# APM32L08x register map
File version: 1.0
CPU: CM0+ r0p0, little endian, MPU, no FPU, 4 interrupt priority bits
Registers are 32-bit, read-write, reset 0x0 unless marked. A register's access mark holds for its fields unless they carry their own. Offsets are from the block's base; [hi:lo] are bit positions.

## CRS — Clock recovery system
Base 0x40006C00
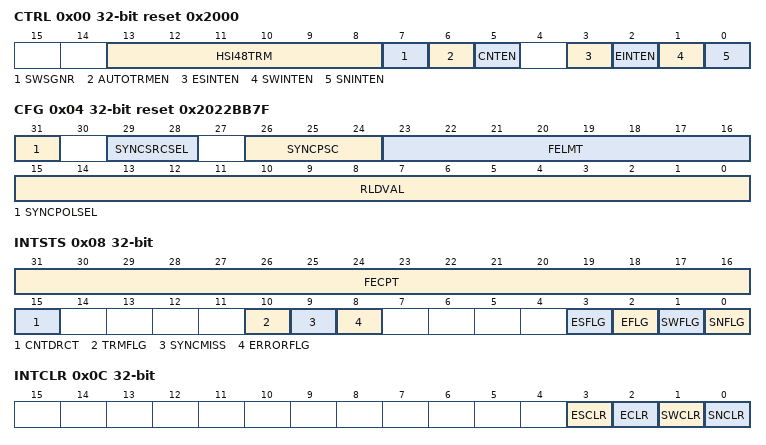
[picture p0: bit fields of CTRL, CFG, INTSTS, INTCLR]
0x00 CTRL reset 0x2000 — control register
  [13:8] HSI48TRM — HSI48 oscillator smooth trimming
  [7] SWSGNR — Generate software SYNC event
  [6] AUTOTRMEN — Automatic trimming enable
  [5] CNTEN — Frequency error counter enable
  [3] ESINTEN — Expected SYNC interrupt enable
  [2] EINTEN — Synchronization or trimming error interrupt enable
  [1] SWINTEN — SYNC warning interrupt enable
  [0] SNINTEN — SYNC event OK interrupt enable
0x04 CFG reset 0x2022BB7F — configuration register
  [31] SYNCPOLSEL — SYNC polarity selection
  [29:28] SYNCSRCSEL — SYNC signal source selection
  [26:24] SYNCPSC — SYNC divider
  [23:16] FELMT — Frequency error limit
  [15:0] RLDVAL — Counter reload value
0x08 INTSTS ro — interrupt and status register
  [31:16] FECPT — Frequency error capture
  [15] CNTDRCT — Frequency error direction
  [10] TRMFLG — Trimming overflow or underflow
  [9] SYNCMISS — SYNC missed
  [8] ERRORFLG — SYNC error
  [3] ESFLG — Expected SYNC flag
  [2] EFLG — Error flag
  [1] SWFLG — SYNC warning flag
  [0] SNFLG — SYNC event OK flag
0x0C INTCLR — interrupt flag clear register
  [3] ESCLR — Expected SYNC clear flag
  [2] ECLR — Error clear flag
  [1] SWCLR — SYNC warning clear flag
  [0] SNCLR — SYNC event OK clear flag

## CRC — Cyclic redundancy check calculation unit
Base 0x40023000
0x00 DATA reset 0xFFFFFFFF
  [31:0] DATA — 32bit Data
0x04 INDATA — Independent data register
  [7:0] INDATA — Independent 8bit Data
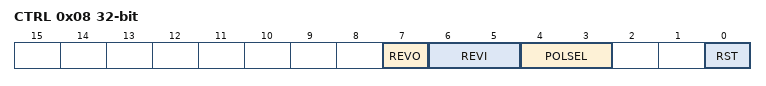
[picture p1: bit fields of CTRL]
0x08 CTRL access per field — Control register
  [7] REVO rw — Reverse output data
  [6:5] REVI rw — Reverse input data
  [4:3] POLSEL rw — Polynomial size
  [0] RST wo — Reset CRC Calculation Unit
0x10 INITVAL reset 0xFFFFFFFF — Initial CRC value
  [31:0] VALUE — Programmable initial CRC value
0x14 POL reset 0x4C11DB7 — polynomial
  [31:0] PPOL — Programmable polynomial

## DAC — Digital-to-analog converter
Base 0x40007400
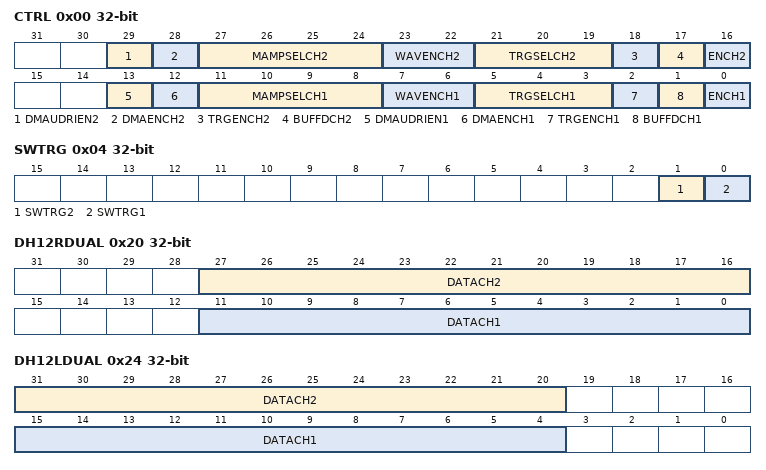
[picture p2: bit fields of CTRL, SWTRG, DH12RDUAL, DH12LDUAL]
0x00 CTRL — control register
  [29] DMAUDRIEN2 — DAC Channel2 DMA Underrun Interrupt Enable
  [28] DMAENCH2 — DAC channel2DMA enable
  [27:24] MAMPSELCH2 — Select DAC Channel2 LFSR Bit Mask/Triangle Wave Amplitude Selector
  [23:22] WAVENCH2 — DAC Channel2 Noise/Triangle Wave Generation Enable
  [21:19] TRGSELCH2 — DAC Channel2 Trigger Source Select
  [18] TRGENCH2 — DAC Channel2 Trigger Enable
  [17] BUFFDCH2 — DAC Channel2 Output Buffer Disable
  [16] ENCH2 — DAC Channel2 Enable
  [13] DMAUDRIEN1 — DAC channel1 DMA Underrun Interrupt enable
  [12] DMAENCH1 — DAC channel1 DMA enable
  [11:8] MAMPSELCH1 — DAC channel1 mask/amplitude selector
  [7:6] WAVENCH1 — DAC channel1 noise/triangle wave generation enable
  [5:3] TRGSELCH1 — DAC channel1 trigger selection
  [2] TRGENCH1 — DAC channel1 trigger enable
  [1] BUFFDCH1 — DAC channel1 output buffer disable
  [0] ENCH1 — DAC channel1 enable
0x04 SWTRG wo — software trigger register
  [1] SWTRG2 — DAC Channel2 Software Trigger Enable
  [0] SWTRG1 — DAC Channel1 Software Trigger Enable
0x08 DH12R1 — channel1 12-bit right-aligned data holding register
  [11:0] DATA — DAC channel1 12-bit right-aligned data
0x0C DH12L1 — channel1 12-bit left-aligned data holding register
  [15:4] DATA — DAC channel1 12-bit left-aligned data
0x10 DH8R1 — channel1 8-bit right-aligned data holding register
  [7:0] DATA — DAC channel1 8-bit right-aligned data
0x14 DH12R2 — channel2 12-bit right-aligned data holding register
  [11:0] DATA — DAC channel2 12-bit right-aligned data
0x18 DH12L2 — channel2 12-bit left-aligned data holding register
  [15:4] DATA — DAC channel2 12-bit left-aligned data
0x1C DH8R2 — channel2 8-bit right-aligned data holding register
  [7:0] DATA — DAC channel2 8-bit right-aligned data
0x20 DH12RDUAL — Dual DAC 12-bit right-aligned data holding register
  [27:16] DATACH2 — DAC channel2 12-bit right-aligned data
  [11:0] DATACH1 — DAC channel1 12-bit right-aligned data
0x24 DH12LDUAL — Dual DAC 12-bit left-aligned data holding register
  [31:20] DATACH2 — DAC channel2 12-bit left-aligned data
  [15:4] DATACH1 — DAC channel1 12-bit left-aligned data
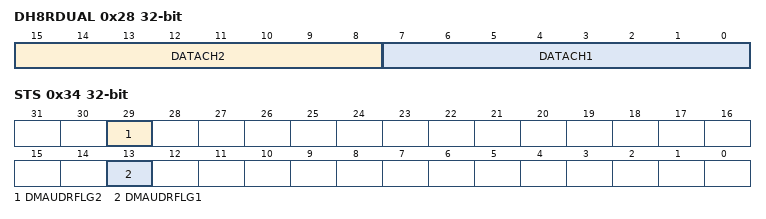
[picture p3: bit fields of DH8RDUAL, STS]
0x28 DH8RDUAL — Dual DAC 8-bit right-aligned data holding register
  [15:8] DATACH2 — DAC channel2 8-bit right-aligned data
  [7:0] DATACH1 — DAC channel1 8-bit right-aligned data
0x2C DATAOCH1 ro — channel1 data output register
  [11:0] DATA — DAC channel1 data output
0x30 DATAOCH2 ro — channel2 data output register
  [11:0] DATA — DAC channel2 data output
0x34 STS — status register
  [29] DMAUDRFLG2 — DAC Channel1 DMA Underrun Flag
  [13] DMAUDRFLG1 — DAC Channel1 DMA Underrun Flag
